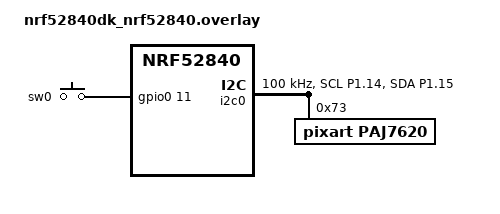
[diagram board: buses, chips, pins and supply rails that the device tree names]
/*
 * Copyright (c) 2025 Paul Timke <ptimkec@live.com>
 * Copyright (c) 2025 Mohamed Haggouna <mohamed.haggouna@gmail.com>
 *
 * SPDX-License-Identifier: Apache-2.0
 */
&i2c0 {
	compatible = "nordic,nrf-twi";
	status = "okay";
	pinctrl-0 = <&i2c0_default>;
	pinctrl-1 = <&i2c0_sleep>;
	pinctrl-names = "default", "sleep";

	paj7620: paj7620@73 {
		compatible = "pixart,paj7620";
		reg = <0x73>;
	};

	clock-frequency = <I2C_BITRATE_STANDARD>;
};

&pinctrl {
	/omit-if-no-ref/ i2c0_default: i2c0_default {
		group1 {
			psels = <NRF_PSEL(TWIM_SCL, 1, 14)>,
				<NRF_PSEL(TWIM_SDA, 1, 15)>;
		};
	};

	/omit-if-no-ref/ i2c0_sleep: i2c0_sleep {
		group1 {
			psels = <NRF_PSEL(TWIM_SCL, 1, 14)>,
				<NRF_PSEL(TWIM_SDA, 1, 15)>;
			low-power-enable;
		};
	};
};

&button0 {
	gpios = <&gpio0 11 (GPIO_PULL_UP | GPIO_ACTIVE_HIGH)>;
	label = "sw0";
};
